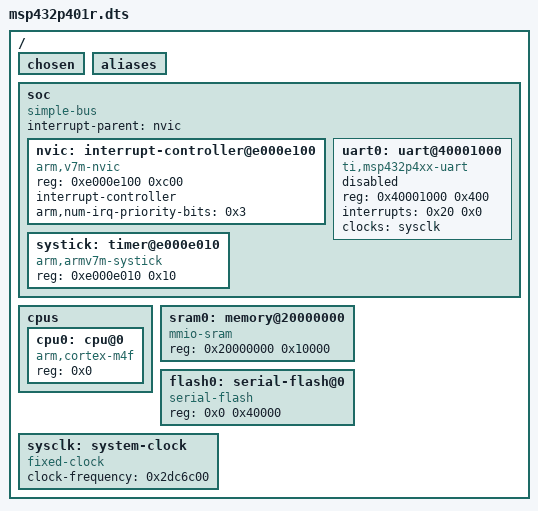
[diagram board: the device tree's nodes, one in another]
/dts-v1/;

/ {
	#address-cells = < 0x1 >;
	#size-cells = < 0x1 >;
	chosen {
	};
	aliases {
	};
	soc {
		#address-cells = < 0x1 >;
		#size-cells = < 0x1 >;
		compatible = "simple-bus";
		interrupt-parent = < &nvic >;
		ranges;
		nvic: interrupt-controller@e000e100 {
			#address-cells = < 0x1 >;
			compatible = "arm,v7m-nvic";
			reg = < 0xe000e100 0xc00 >;
			interrupt-controller;
			#interrupt-cells = < 0x2 >;
			arm,num-irq-priority-bits = < 0x3 >;
			phandle = < 0x1 >;
		};
		systick: timer@e000e010 {
			compatible = "arm,armv7m-systick";
			reg = < 0xe000e010 0x10 >;
		};
		uart0: uart@40001000 {
			compatible = "ti,msp432p4xx-uart";
			reg = < 0x40001000 0x400 >;
			interrupts = < 0x20 0x0 >;
			clocks = < &sysclk >;
			status = "disabled";
		};
	};
	cpus {
		#address-cells = < 0x1 >;
		#size-cells = < 0x0 >;
		cpu0: cpu@0 {
			compatible = "arm,cortex-m4f";
			reg = < 0x0 >;
		};
	};
	sram0: memory@20000000 {
		compatible = "mmio-sram";
		reg = < 0x20000000 0x10000 >;
	};
	flash0: serial-flash@0 {
		compatible = "serial-flash";
		reg = < 0x0 0x40000 >;
	};
	sysclk: system-clock {
		compatible = "fixed-clock";
		clock-frequency = < 0x2dc6c00 >;
		#clock-cells = < 0x0 >;
		phandle = < 0x2 >;
	};
};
